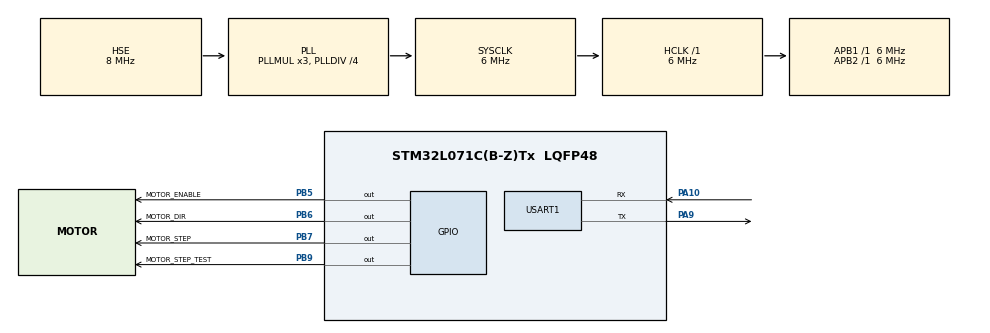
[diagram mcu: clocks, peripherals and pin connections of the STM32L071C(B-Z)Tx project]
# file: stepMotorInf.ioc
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IWDG.Prescaler=IWDG_PRESCALER_32
Mcu.Family=STM32L0
Mcu.Name=STM32L071C(B-Z)Tx
Mcu.Package=LQFP48
NVIC.TIM3_IRQn=true\:0\:0\:false\:false\:true\:true\:true
NVIC.USART1_IRQn=true\:0\:0\:false\:false\:true\:true\:true
PA10.Mode=Asynchronous
PA10.Signal=USART1_RX
PA9.Mode=Asynchronous
PA9.Signal=USART1_TX
PB5.GPIO_Label=MOTOR_ENABLE
PB5.PinState=GPIO_PIN_SET
PB5.Signal=GPIO_Output
PB6.GPIO_Label=MOTOR_DIR
PB6.PinState=GPIO_PIN_SET
PB6.Signal=GPIO_Output
PB7.GPIO_Label=MOTOR_STEP
PB7.PinState=GPIO_PIN_SET
PB7.Signal=GPIO_Output
PB9.GPIO_Label=MOTOR_STEP_TEST
PB9.Signal=GPIO_Output
PH0-OSC_IN.Mode=HSE-External-Oscillator
PH0-OSC_IN.Signal=RCC_OSC_IN
PH1-OSC_OUT.Mode=HSE-External-Oscillator
PH1-OSC_OUT.Signal=RCC_OSC_OUT
ProjectManager.HeapSize=0x200
ProjectManager.StackSize=0x400
ProjectManager.TargetToolchain=Makefile
RCC.AHBFreq_Value=6000000
RCC.APB1Freq_Value=6000000
RCC.APB1TimFreq_Value=6000000
RCC.APB2Freq_Value=6000000
RCC.APB2TimFreq_Value=6000000
RCC.HCLKFreq_Value=6000000
RCC.HSE_VALUE=8000000
RCC.HSI16_VALUE=16000000
RCC.HSI_VALUE=16000000
RCC.LSE_VALUE=32768
RCC.MSI_VALUE=2097000
RCC.PLLDIV=RCC_PLLDIV_4
RCC.PLLSourceVirtual=RCC_PLLSOURCE_HSE
RCC.SYSCLKFreq_VALUE=6000000
RCC.SYSCLKSource=RCC_SYSCLKSOURCE_PLLCLK
RCC.VCOOutputFreq_Value=24000000
TIM3.AutoReloadPreload=TIM_AUTORELOAD_PRELOAD_ENABLE
TIM3.Period=4999
TIM3.Prescaler=(SystemCoreClock/1000000)-1
USART1.VirtualMode-Asynchronous=VM_ASYNC
VP_IWDG_VS_IWDG.Mode=IWDG_Activate
VP_TIM3_VS_ClockSourceINT.Mode=Internal
board=custom

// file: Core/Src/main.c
/* USER CODE BEGIN Header */
/**
  ******************************************************************************
  * @file           : main.c
  * @brief          : Main program body
  ******************************************************************************
  * @attention
  *
  * Copyright (c) 2023 STMicroelectronics.
  * All rights reserved.
  *
  * This software is licensed under terms that can be found in the LICENSE file
  * in the root directory of this software component.
  * If no LICENSE file comes with this software, it is provided AS-IS.
  *
  ******************************************************************************
  */
/* USER CODE END Header */
#include "main.h"

/* USER CODE BEGIN Includes */
#include "app/app_main.h"
/* USER CODE END Includes */

IWDG_HandleTypeDef hiwdg;

TIM_HandleTypeDef htim3;

UART_HandleTypeDef huart1;

void SystemClock_Config(void);
static void MX_GPIO_Init(void);
static void MX_USART1_UART_Init(void);
static void MX_TIM3_Init(void);
static void MX_IWDG_Init(void);

/* USER CODE BEGIN 0 */
HAL_Context global_hal = {0,};      // Global HAL instance
HAL_Context *gHAL = &global_hal;
/* USER CODE END 0 */

int main(void)
{

  /* MCU Configuration--------------------------------------------------------*/

  /* Reset of all peripherals, Initializes the Flash interface and the Systick. */
  HAL_Init();

  /* Configure the system clock */
  SystemClock_Config();

  /* Initialize all configured peripherals */
  MX_GPIO_Init();
  MX_USART1_UART_Init();
  MX_TIM3_Init();
  MX_IWDG_Init();
  /* USER CODE BEGIN 2 */
  gHAL->huart_dbg = &huart1;
  gHAL->step_timer = &htim3;
  if(hiwdg.Instance)  gHAL->iwdg = &hiwdg;
  app_init();
  /* USER CODE END 2 */

  /* Infinite loop */
  /* USER CODE BEGIN WHILE */
  while (1)
  {
    app_run();
    /* USER CODE END WHILE */

  }
}

void SystemClock_Config(void)
{
  RCC_OscInitTypeDef RCC_OscInitStruct = {0};
  RCC_ClkInitTypeDef RCC_ClkInitStruct = {0};
  RCC_PeriphCLKInitTypeDef PeriphClkInit = {0};

  /** Configure the main internal regulator output voltage
  */
  __HAL_PWR_VOLTAGESCALING_CONFIG(PWR_REGULATOR_VOLTAGE_SCALE1);
  /** Initializes the RCC Oscillators according to the specified parameters
  * in the RCC_OscInitTypeDef structure.
  */
  RCC_OscInitStruct.OscillatorType = RCC_OSCILLATORTYPE_LSI|RCC_OSCILLATORTYPE_HSE;
  RCC_OscInitStruct.HSEState = RCC_HSE_ON;
  RCC_OscInitStruct.LSIState = RCC_LSI_ON;
  RCC_OscInitStruct.PLL.PLLState = RCC_PLL_ON;
  RCC_OscInitStruct.PLL.PLLSource = RCC_PLLSOURCE_HSE;
  RCC_OscInitStruct.PLL.PLLMUL = RCC_PLLMUL_3;
  RCC_OscInitStruct.PLL.PLLDIV = RCC_PLLDIV_4;
  if (HAL_RCC_OscConfig(&RCC_OscInitStruct) != HAL_OK)
  {
    Error_Handler();
  }
  /** Initializes the CPU, AHB and APB buses clocks
  */
  RCC_ClkInitStruct.ClockType = RCC_CLOCKTYPE_HCLK|RCC_CLOCKTYPE_SYSCLK
                              |RCC_CLOCKTYPE_PCLK1|RCC_CLOCKTYPE_PCLK2;
  RCC_ClkInitStruct.SYSCLKSource = RCC_SYSCLKSOURCE_PLLCLK;
  RCC_ClkInitStruct.AHBCLKDivider = RCC_SYSCLK_DIV1;
  RCC_ClkInitStruct.APB1CLKDivider = RCC_HCLK_DIV1;
  RCC_ClkInitStruct.APB2CLKDivider = RCC_HCLK_DIV1;

  if (HAL_RCC_ClockConfig(&RCC_ClkInitStruct, FLASH_LATENCY_0) != HAL_OK)
  {
    Error_Handler();
  }
  PeriphClkInit.PeriphClockSelection = RCC_PERIPHCLK_USART1;
  PeriphClkInit.Usart1ClockSelection = RCC_USART1CLKSOURCE_PCLK2;
  if (HAL_RCCEx_PeriphCLKConfig(&PeriphClkInit) != HAL_OK)
  {
    Error_Handler();
  }
}

static void MX_IWDG_Init(void)
{

  hiwdg.Instance = IWDG;
  hiwdg.Init.Prescaler = IWDG_PRESCALER_32;
  hiwdg.Init.Window = 4095;
  hiwdg.Init.Reload = 4095;
  if (HAL_IWDG_Init(&hiwdg) != HAL_OK)
  {
    Error_Handler();
  }

}

static void MX_TIM3_Init(void)
{

  /* USER CODE BEGIN TIM3_Init 0 */
  return;
  /* USER CODE END TIM3_Init 0 */

  TIM_ClockConfigTypeDef sClockSourceConfig = {0};
  TIM_MasterConfigTypeDef sMasterConfig = {0};

  htim3.Instance = TIM3;
  htim3.Init.Prescaler = (SystemCoreClock/1000000)-1;
  htim3.Init.CounterMode = TIM_COUNTERMODE_UP;
  htim3.Init.Period = 4999;
  htim3.Init.ClockDivision = TIM_CLOCKDIVISION_DIV1;
  htim3.Init.AutoReloadPreload = TIM_AUTORELOAD_PRELOAD_ENABLE;
  if (HAL_TIM_Base_Init(&htim3) != HAL_OK)
  {
    Error_Handler();
  }
  sClockSourceConfig.ClockSource = TIM_CLOCKSOURCE_INTERNAL;
  if (HAL_TIM_ConfigClockSource(&htim3, &sClockSourceConfig) != HAL_OK)
  {
    Error_Handler();
  }
  sMasterConfig.MasterOutputTrigger = TIM_TRGO_RESET;
  sMasterConfig.MasterSlaveMode = TIM_MASTERSLAVEMODE_DISABLE;
  if (HAL_TIMEx_MasterConfigSynchronization(&htim3, &sMasterConfig) != HAL_OK)
  {
    Error_Handler();
  }

}

static void MX_USART1_UART_Init(void)
{

  huart1.Instance = USART1;
  huart1.Init.BaudRate = 115200;
  huart1.Init.WordLength = UART_WORDLENGTH_8B;
  huart1.Init.StopBits = UART_STOPBITS_1;
  huart1.Init.Parity = UART_PARITY_NONE;
  huart1.Init.Mode = UART_MODE_TX_RX;
  huart1.Init.HwFlowCtl = UART_HWCONTROL_NONE;
  huart1.Init.OverSampling = UART_OVERSAMPLING_16;
  huart1.Init.OneBitSampling = UART_ONE_BIT_SAMPLE_DISABLE;
  huart1.AdvancedInit.AdvFeatureInit = UART_ADVFEATURE_NO_INIT;
  if (HAL_UART_Init(&huart1) != HAL_OK)
  {
    Error_Handler();
  }

}

static void MX_GPIO_Init(void)
{
  GPIO_InitTypeDef GPIO_InitStruct = {0};

  /* GPIO Ports Clock Enable */
  __HAL_RCC_GPIOH_CLK_ENABLE();
  __HAL_RCC_GPIOA_CLK_ENABLE();
  __HAL_RCC_GPIOB_CLK_ENABLE();

  /*Configure GPIO pin Output Level */
  HAL_GPIO_WritePin(GPIOB, MOTOR_ENABLE_Pin|MOTOR_DIR_Pin|MOTOR_STEP_Pin, GPIO_PIN_SET);

  /*Configure GPIO pin Output Level */
  HAL_GPIO_WritePin(MOTOR_STEP_TEST_GPIO_Port, MOTOR_STEP_TEST_Pin, GPIO_PIN_RESET);

  /*Configure GPIO pins : MOTOR_ENABLE_Pin MOTOR_DIR_Pin MOTOR_STEP_Pin MOTOR_STEP_TEST_Pin */
  GPIO_InitStruct.Pin = MOTOR_ENABLE_Pin|MOTOR_DIR_Pin|MOTOR_STEP_Pin|MOTOR_STEP_TEST_Pin;
  GPIO_InitStruct.Mode = GPIO_MODE_OUTPUT_PP;
  GPIO_InitStruct.Pull = GPIO_NOPULL;
  GPIO_InitStruct.Speed = GPIO_SPEED_FREQ_LOW;
  HAL_GPIO_Init(GPIOB, &GPIO_InitStruct);

}

void Error_Handler(void)
{
  __disable_irq();
  while (1)
  {
  }
}
